AUTOSAR XML (schema 3.1.2)
package /Components/SWC_CoClLASl
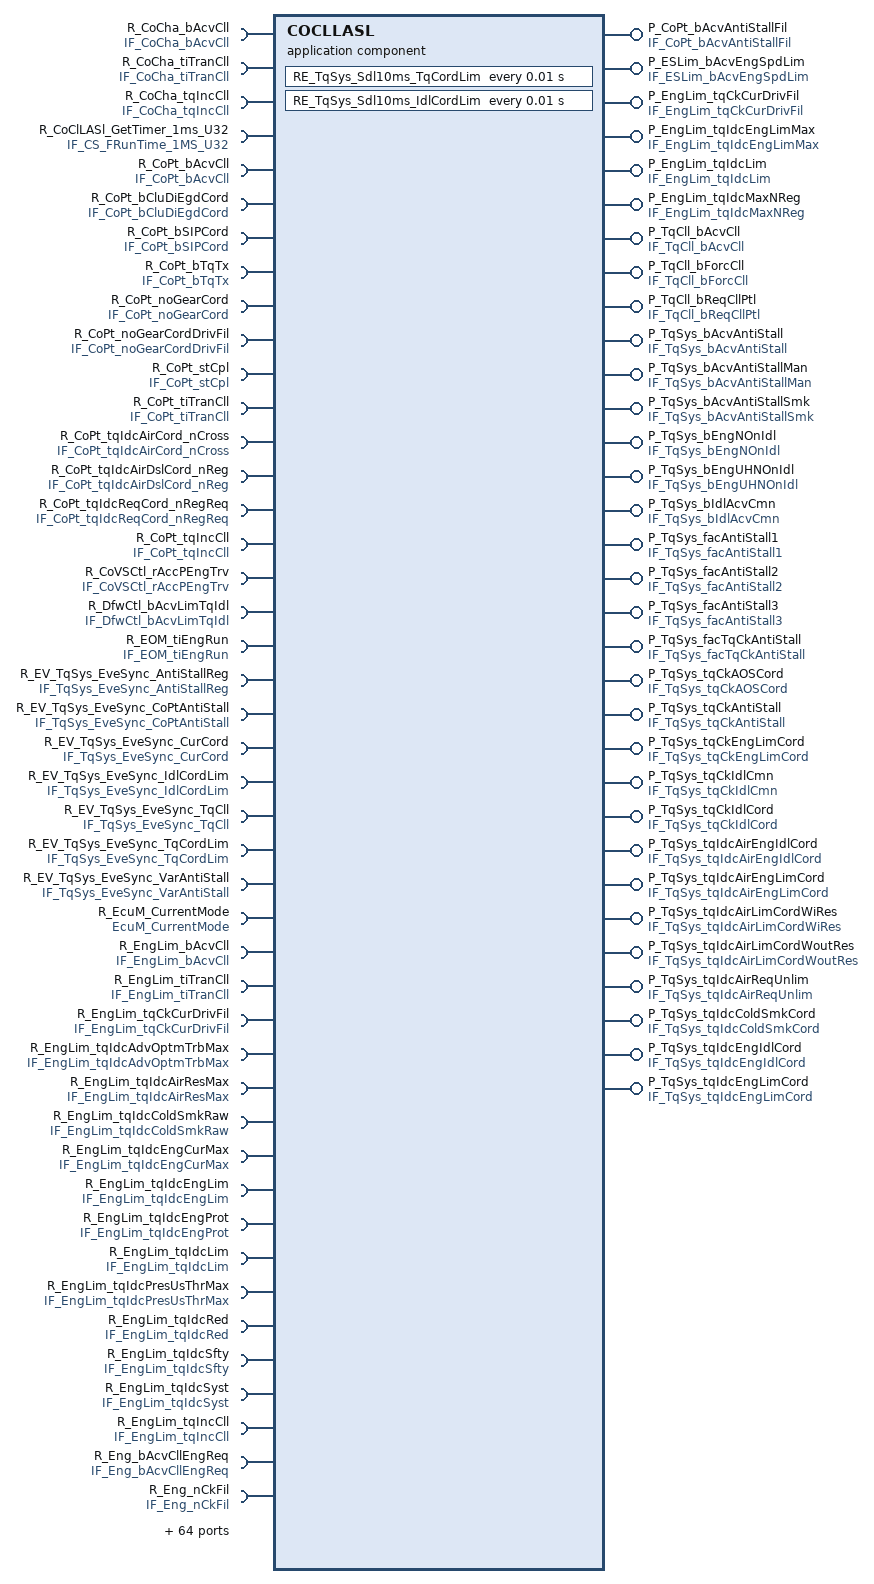
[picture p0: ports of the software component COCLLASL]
  application software component type COCLLASL  # CoClLASl
    32 x provide port:
      P_CoPt_bAcvAntiStallFil: unqueued-sender-com-spec{data-element=CoPt_bAcvAntiStallFil, can-invalidate=false, init-value=ConstantValue}, provided-interface=IF_CoPt_bAcvAntiStallFil  # Requirement: 01552_10_01788-CoClLASl.I103(0)
      P_ESLim_bAcvEngSpdLim: unqueued-sender-com-spec{data-element=ESLim_bAcvEngSpdLim, can-invalidate=false, init-value=ConstantValue1}, provided-interface=IF_ESLim_bAcvEngSpdLim  # Requirement: 01552_10_01788-CoClLASl.I082(0)
      P_EngLim_tqCkCurDrivFil: unqueued-sender-com-spec{data-element=EngLim_tqCkCurDrivFil, can-invalidate=false, init-value=ConstantValue3}, provided-interface=IF_EngLim_tqCkCurDrivFil  # Requirement: 01552_10_01788-CoClLASl.I083(0)
      P_EngLim_tqIdcEngLimMax: unqueued-sender-com-spec{data-element=EngLim_tqIdcEngLimMax, can-invalidate=false, init-value=ConstantValue5}, provided-interface=IF_EngLim_tqIdcEngLimMax  # Requirement: 01552_10_01788-CoClLASl.I086(0)
      P_EngLim_tqIdcLim: unqueued-sender-com-spec{data-element=EngLim_tqIdcLim, can-invalidate=false, init-value=ConstantValue7}, provided-interface=IF_EngLim_tqIdcLim  # Requirement: 01552_10_01788-CoClLASl.I087(0)
      P_EngLim_tqIdcMaxNReg: unqueued-sender-com-spec{data-element=EngLim_tqIdcMaxNReg, can-invalidate=false, init-value=ConstantValue9}, provided-interface=IF_EngLim_tqIdcMaxNReg  # Requirement: 01552_10_01788-CoClLASl.I088(0)
      P_TqCll_bAcvCll: unqueued-sender-com-spec{data-element=TqCll_bAcvCll, can-invalidate=false, init-value=ConstantValue11}, provided-interface=IF_TqCll_bAcvCll  # Requirement: 01552_10_01788-CoClLASl.I048(0)
      P_TqCll_bForcCll: unqueued-sender-com-spec{data-element=TqCll_bForcCll, can-invalidate=false, init-value=ConstantValue13}, provided-interface=IF_TqCll_bForcCll  # Requirement: 01552_10_01788-CoClLASl.I049(0)
      P_TqCll_bReqCllPtl: unqueued-sender-com-spec{data-element=TqCll_bReqCllPtl, can-invalidate=false, init-value=ConstantValue15}, provided-interface=IF_TqCll_bReqCllPtl  # Requirement: 01552_10_01788-CoClLASl.I047(0)
      P_TqSys_bAcvAntiStall: unqueued-sender-com-spec{data-element=TqSys_bAcvAntiStall, can-invalidate=false, init-value=ConstantValue17}, provided-interface=IF_TqSys_bAcvAntiStall  # Requirement: 01552_10_01788-CoClLASl.I003(0)
      P_TqSys_bAcvAntiStallMan: unqueued-sender-com-spec{data-element=TqSys_bAcvAntiStallMan, can-invalidate=false, init-value=ConstantValue19}, provided-interface=IF_TqSys_bAcvAntiStallMan  # Requirement: 01552_10_01788-CoClLASl.I146(0)
      P_TqSys_bAcvAntiStallSmk: unqueued-sender-com-spec{data-element=TqSys_bAcvAntiStallSmk, can-invalidate=false, init-value=ConstantValue21}, provided-interface=IF_TqSys_bAcvAntiStallSmk  # Requirement: 01552_10_01788-CoClLASl.I102(0)
      P_TqSys_bEngNOnIdl: unqueued-sender-com-spec{data-element=TqSys_bEngNOnIdl, can-invalidate=false, init-value=ConstantValue23}, provided-interface=IF_TqSys_bEngNOnIdl  # Requirement: 01552_10_01788-CoClLASl.I004(0)
      P_TqSys_bEngUHNOnIdl: unqueued-sender-com-spec{data-element=TqSys_bEngUHNOnIdl, can-invalidate=false, init-value=ConstantValue25}, provided-interface=IF_TqSys_bEngUHNOnIdl  # Requirement: 01552_10_01788-CoClLASl.I005(0)
      P_TqSys_bIdlAcvCmn: unqueued-sender-com-spec{data-element=TqSys_bIdlAcvCmn, can-invalidate=false, init-value=ConstantValue27}, provided-interface=IF_TqSys_bIdlAcvCmn  # Requirement: 01552_10_01788-CoClLASl.I006(0)
      P_TqSys_facAntiStall1: unqueued-sender-com-spec{data-element=TqSys_facAntiStall1, can-invalidate=false, init-value=ConstantValue29}, provided-interface=IF_TqSys_facAntiStall1  # Requirement: 01552_10_01788-CoClLASl.I112(1)
      P_TqSys_facAntiStall2: unqueued-sender-com-spec{data-element=TqSys_facAntiStall2, can-invalidate=false, init-value=ConstantValue31}, provided-interface=IF_TqSys_facAntiStall2  # Requirement: 01552_10_01788-CoClLASl.I113(1)
      P_TqSys_facAntiStall3: unqueued-sender-com-spec{data-element=TqSys_facAntiStall3, can-invalidate=false, init-value=ConstantValue33}, provided-interface=IF_TqSys_facAntiStall3  # Requirement: 01552_10_01788-CoClLASl.I114(1)
      P_TqSys_facTqCkAntiStall: unqueued-sender-com-spec{data-element=TqSys_facTqCkAntiStall, can-invalidate=false, init-value=ConstantValue35}, provided-interface=IF_TqSys_facTqCkAntiStall  # Requirement: 01552_10_01788-CoClLASl.I115(1)
      P_TqSys_tqCkAOSCord: unqueued-sender-com-spec{data-element=TqSys_tqCkAOSCord, can-invalidate=false, init-value=ConstantValue37}, provided-interface=IF_TqSys_tqCkAOSCord  # Requirement: 01552_10_01788-CoClLASl.I076(0)
      P_TqSys_tqCkAntiStall: unqueued-sender-com-spec{data-element=TqSys_tqCkAntiStall, can-invalidate=false, init-value=ConstantValue39}, provided-interface=IF_TqSys_tqCkAntiStall  # Requirement: 01552_10_01788-CoClLASl.I147(1)
      P_TqSys_tqCkEngLimCord: unqueued-sender-com-spec{data-element=TqSys_tqCkEngLimCord, can-invalidate=false, init-value=ConstantValue41}, provided-interface=IF_TqSys_tqCkEngLimCord  # Requirement: 01552_10_01788-CoClLASl.I050(0)
      P_TqSys_tqCkIdlCmn: unqueued-sender-com-spec{data-element=TqSys_tqCkIdlCmn, can-invalidate=false, init-value=ConstantValue43}, provided-interface=IF_TqSys_tqCkIdlCmn  # Requirement: 01552_10_01788-CoClLASl.I007(0)
      P_TqSys_tqCkIdlCord: unqueued-sender-com-spec{data-element=TqSys_tqCkIdlCord, can-invalidate=false, init-value=ConstantValue45}, provided-interface=IF_TqSys_tqCkIdlCord  # Requirement: 01552_10_01788-CoClLASl.I008(0)
      P_TqSys_tqIdcAirEngIdlCord: unqueued-sender-com-spec{data-element=TqSys_tqIdcAirEngIdlCord, can-invalidate=false, init-value=ConstantValue47}, provided-interface=IF_TqSys_tqIdcAirEngIdlCord  # Requirement: 01552_10_01788-CoClLASl.I001(0)
      P_TqSys_tqIdcAirEngLimCord: unqueued-sender-com-spec{data-element=TqSys_tqIdcAirEngLimCord, can-invalidate=false, init-value=ConstantValue49}, provided-interface=IF_TqSys_tqIdcAirEngLimCord  # Requirement: 01552_10_01788-CoClLASl.I009(0)
      P_TqSys_tqIdcAirLimCordWiRes: unqueued-sender-com-spec{data-element=TqSys_tqIdcAirLimCordWiRes, can-invalidate=false, init-value=ConstantValue51}, provided-interface=IF_TqSys_tqIdcAirLimCordWiRes  # Requirement: 01552_10_01788-CoClLASl.I010(1)
      P_TqSys_tqIdcAirLimCordWoutRes: unqueued-sender-com-spec{data-element=TqSys_tqIdcAirLimCordWoutRes, can-invalidate=false, init-value=ConstantValue53}, provided-interface=IF_TqSys_tqIdcAirLimCordWoutRes  # Requirement: 01552_10_01788-CoClLASl.I011(0)
      P_TqSys_tqIdcAirReqUnlim: unqueued-sender-com-spec{data-element=TqSys_tqIdcAirReqUnlim, can-invalidate=false, init-value=ConstantValue55}, provided-interface=IF_TqSys_tqIdcAirReqUnlim  # Requirement: 01552_10_01788-CoClLASl.I002(0)
      P_TqSys_tqIdcColdSmkCord: unqueued-sender-com-spec{data-element=TqSys_tqIdcColdSmkCord, can-invalidate=false, init-value=ConstantValue57}, provided-interface=IF_TqSys_tqIdcColdSmkCord  # Requirement: 01552_10_01788-CoClLASl.I144(0)
      P_TqSys_tqIdcEngIdlCord: unqueued-sender-com-spec{data-element=TqSys_tqIdcEngIdlCord, can-invalidate=false, init-value=ConstantValue59}, provided-interface=IF_TqSys_tqIdcEngIdlCord  # Requirement: 01552_10_01788-CoClLASl.I012(0)
      P_TqSys_tqIdcEngLimCord: unqueued-sender-com-spec{data-element=TqSys_tqIdcEngLimCord, can-invalidate=false, init-value=ConstantValue61}, provided-interface=IF_TqSys_tqIdcEngLimCord  # Requirement: 01552_10_01788-CoClLASl.I013(0)
    108 x require port:
      R_CoCha_bAcvCll: unqueued-receiver-com-spec{data-element=CoCha_bAcvCll, init-value=ConstantValue63, resync-time=0}, required-interface=IF_CoCha_bAcvCll  # Requirement: 01552_10_01788-CoClLASl.I051(0)
      R_CoCha_tiTranCll: unqueued-receiver-com-spec{data-element=CoCha_tiTranCll, init-value=ConstantValue65, resync-time=0}, required-interface=IF_CoCha_tiTranCll  # Requirement: 01552_10_01788-CoClLASl.I052(0)
      R_CoCha_tqIncCll: unqueued-receiver-com-spec{data-element=CoCha_tqIncCll, init-value=ConstantValue67, resync-time=0}, required-interface=IF_CoCha_tqIncCll  # Requirement: 01552_10_01788-CoClLASl.I053(0)
      R_CoClLASl_GetTimer_1ms_U32: required-interface=IF_CS_FRunTime_1MS_U32
      R_CoPt_bAcvCll: unqueued-receiver-com-spec{data-element=CoPt_bAcvCll, init-value=ConstantValue69, resync-time=0}, required-interface=IF_CoPt_bAcvCll  # Requirement: 01552_10_01788-CoClLASl.I054(0)
      R_CoPt_bCluDiEgdCord: unqueued-receiver-com-spec{data-element=CoPt_bCluDiEgdCord, init-value=ConstantValue71, resync-time=0}, required-interface=IF_CoPt_bCluDiEgdCord  # Requirement: 01552_10_01788-CoClLASl.I116(0)
      R_CoPt_bSIPCord: unqueued-receiver-com-spec{data-element=CoPt_bSIPCord, init-value=ConstantValue73, resync-time=0}, required-interface=IF_CoPt_bSIPCord  # Requirement: 01552_10_01788-CoClLASl.I016(0)
      R_CoPt_bTqTx: unqueued-receiver-com-spec{data-element=CoPt_bTqTx, init-value=ConstantValue75, resync-time=0}, required-interface=IF_CoPt_bTqTx  # Requirement: 01552_10_01788-CoClLASl.I105(0)
      R_CoPt_noGearCord: unqueued-receiver-com-spec{data-element=CoPt_noGearCord, init-value=ConstantValue77, resync-time=0}, required-interface=IF_CoPt_noGearCord  # Requirement: 01552_10_01788-CoClLASl.I089(0)
      R_CoPt_noGearCordDrivFil: unqueued-receiver-com-spec{data-element=CoPt_noGearCordDrivFil, init-value=ConstantValue79, resync-time=0}, required-interface=IF_CoPt_noGearCordDrivFil  # Requirement: 01552_10_01788-CoClLASl.I055(0)
      R_CoPt_stCpl: unqueued-receiver-com-spec{data-element=CoPt_stCpl, init-value=ConstantValue81, resync-time=0}, required-interface=IF_CoPt_stCpl  # Requirement: 01552_10_01788-CoClLASl.I106(0)
      R_CoPt_tiTranCll: unqueued-receiver-com-spec{data-element=CoPt_tiTranCll, init-value=ConstantValue83, resync-time=0}, required-interface=IF_CoPt_tiTranCll  # Requirement: 01552_10_01788-CoClLASl.I056(0)
      R_CoPt_tqIdcAirCord_nCross: unqueued-receiver-com-spec{data-element=CoPt_tqIdcAirCord_nCross, init-value=ConstantValue85, resync-time=0}, required-interface=IF_CoPt_tqIdcAirCord_nCross  # Requirement: 01552_10_01788-CoClLASl.I017(0)
      R_CoPt_tqIdcAirDslCord_nReg: unqueued-receiver-com-spec{data-element=CoPt_tqIdcAirDslCord_nReg, init-value=ConstantValue87, resync-time=0}, required-interface=IF_CoPt_tqIdcAirDslCord_nReg  # Requirement: 01552_10_01788-CoClLASl.I018(0)
      R_CoPt_tqIdcReqCord_nRegReq: unqueued-receiver-com-spec{data-element=CoPt_tqIdcReqCord_nRegReq, init-value=ConstantValue89, resync-time=0}, required-interface=IF_CoPt_tqIdcReqCord_nRegReq  # Requirement: 01552_10_01788-CoClLASl.I019(0)
      R_CoPt_tqIncCll: unqueued-receiver-com-spec{data-element=CoPt_tqIncCll, init-value=ConstantValue91, resync-time=0}, required-interface=IF_CoPt_tqIncCll  # Requirement: 01552_10_01788-CoClLASl.I057(0)
      R_CoVSCtl_rAccPEngTrv: unqueued-receiver-com-spec{data-element=CoVSCtl_rAccPEngTrv, init-value=ConstantValue93, resync-time=0}, required-interface=IF_CoVSCtl_rAccPEngTrv  # Requirement: 01552_10_01788-CoClLASl.I020(0)
      R_DfwCtl_bAcvLimTqIdl: unqueued-receiver-com-spec{data-element=DfwCtl_bAcvLimTqIdl, init-value=ConstantValue95, resync-time=0}, required-interface=IF_DfwCtl_bAcvLimTqIdl  # Requirement: 01552_10_01788-CoClLASl.I021(2)
      R_EOM_tiEngRun: unqueued-receiver-com-spec{data-element=EOM_tiEngRun, init-value=ConstantValue97, resync-time=0}, required-interface=IF_EOM_tiEngRun  # Requirement: 01552_10_01788-CoClLASl.I117(0)
      R_EV_TqSys_EveSync_AntiStallReg: unqueued-receiver-com-spec{data-element=EV_TqSys_EveSync_AntiStallReg, init-value=ConstantValue99, resync-time=0}, required-interface=IF_TqSys_EveSync_AntiStallReg
      R_EV_TqSys_EveSync_CoPtAntiStall: unqueued-receiver-com-spec{data-element=EV_TqSys_EveSync_CoPtAntiStall, init-value=ConstantValue101, resync-time=0}, required-interface=IF_TqSys_EveSync_CoPtAntiStall
      R_EV_TqSys_EveSync_CurCord: unqueued-receiver-com-spec{data-element=EV_TqSys_EveSync_CurCord, init-value=ConstantValue103, resync-time=0}, required-interface=IF_TqSys_EveSync_CurCord
      R_EV_TqSys_EveSync_IdlCordLim: unqueued-receiver-com-spec{data-element=EV_TqSys_EveSync_IdlCordLim, init-value=ConstantValue105, resync-time=0}, required-interface=IF_TqSys_EveSync_IdlCordLim
      R_EV_TqSys_EveSync_TqCll: unqueued-receiver-com-spec{data-element=EV_TqSys_EveSync_TqCll, init-value=ConstantValue107, resync-time=0}, required-interface=IF_TqSys_EveSync_TqCll
      R_EV_TqSys_EveSync_TqCordLim: unqueued-receiver-com-spec{data-element=EV_TqSys_EveSync_TqCordLim, init-value=ConstantValue109, resync-time=0}, required-interface=IF_TqSys_EveSync_TqCordLim
      R_EV_TqSys_EveSync_VarAntiStall: unqueued-receiver-com-spec{data-element=EV_TqSys_EveSync_VarAntiStall, init-value=ConstantValue111, resync-time=0}, required-interface=IF_TqSys_EveSync_VarAntiStall
      R_EcuM_CurrentMode: required-interface=EcuM_CurrentMode  # Requirement: 01552_09_00532-SSTG-C007(0)
      R_EngLim_bAcvCll: unqueued-receiver-com-spec{data-element=EngLim_bAcvCll, init-value=ConstantValue113, resync-time=0}, required-interface=IF_EngLim_bAcvCll  # Requirement: 01552_10_01788-CoClLASl.I059(0)
      R_EngLim_tiTranCll: unqueued-receiver-com-spec{data-element=EngLim_tiTranCll, init-value=ConstantValue115, resync-time=0}, required-interface=IF_EngLim_tiTranCll  # Requirement: 01552_10_01788-CoClLASl.I060(0)
      R_EngLim_tqCkCurDrivFil: unqueued-receiver-com-spec{data-element=EngLim_tqCkCurDrivFil, init-value=ConstantValue117, resync-time=0}, required-interface=IF_EngLim_tqCkCurDrivFil  # Requirement: 01552_10_01788-CoClLASl.I077(0)
      R_EngLim_tqIdcAdvOptmTrbMax: unqueued-receiver-com-spec{data-element=EngLim_tqIdcAdvOptmTrbMax, init-value=ConstantValue119, resync-time=0}, required-interface=IF_EngLim_tqIdcAdvOptmTrbMax  # Requirement: 01552_10_01788-CoClLASl.I090(0)
      R_EngLim_tqIdcAirResMax: unqueued-receiver-com-spec{data-element=EngLim_tqIdcAirResMax, init-value=ConstantValue121, resync-time=0}, required-interface=IF_EngLim_tqIdcAirResMax  # Requirement: 01552_10_01788-CoClLASl.I091(0)
      R_EngLim_tqIdcColdSmkRaw: unqueued-receiver-com-spec{data-element=EngLim_tqIdcColdSmkRaw, init-value=ConstantValue123, resync-time=0}, required-interface=IF_EngLim_tqIdcColdSmkRaw  # Requirement: 01552_10_01788-CoClLASl.I024(0)
      R_EngLim_tqIdcEngCurMax: unqueued-receiver-com-spec{data-element=EngLim_tqIdcEngCurMax, init-value=ConstantValue125, resync-time=0}, required-interface=IF_EngLim_tqIdcEngCurMax  # Requirement: 01552_10_01788-CoClLASl.I061(0)
      R_EngLim_tqIdcEngLim: unqueued-receiver-com-spec{data-element=EngLim_tqIdcEngLim, init-value=ConstantValue127, resync-time=0}, required-interface=IF_EngLim_tqIdcEngLim  # Requirement: 01552_10_01788-CoClLASl.I092(0)
      R_EngLim_tqIdcEngProt: unqueued-receiver-com-spec{data-element=EngLim_tqIdcEngProt, init-value=ConstantValue129, resync-time=0}, required-interface=IF_EngLim_tqIdcEngProt  # Requirement: 01552_10_01788-CoClLASl.I093(0)
      R_EngLim_tqIdcLim: unqueued-receiver-com-spec{data-element=EngLim_tqIdcLim, init-value=ConstantValue131, resync-time=0}, required-interface=IF_EngLim_tqIdcLim  # Requirement: 01552_10_01788-CoClLASl.I025(0)
      R_EngLim_tqIdcPresUsThrMax: unqueued-receiver-com-spec{data-element=EngLim_tqIdcPresUsThrMax, init-value=ConstantValue133, resync-time=0}, required-interface=IF_EngLim_tqIdcPresUsThrMax  # Requirement: 01552_10_01788-CoClLASl.I094(0)
      R_EngLim_tqIdcRed: unqueued-receiver-com-spec{data-element=EngLim_tqIdcRed, init-value=ConstantValue135, resync-time=0}, required-interface=IF_EngLim_tqIdcRed  # Requirement: 01552_10_01788-CoClLASl.I026(0)
      R_EngLim_tqIdcSfty: unqueued-receiver-com-spec{data-element=EngLim_tqIdcSfty, init-value=ConstantValue137, resync-time=0}, required-interface=IF_EngLim_tqIdcSfty  # Requirement: 01552_10_01788-CoClLASl.I095(0)
      R_EngLim_tqIdcSyst: unqueued-receiver-com-spec{data-element=EngLim_tqIdcSyst, init-value=ConstantValue139, resync-time=0}, required-interface=IF_EngLim_tqIdcSyst  # Requirement: 01552_10_01788-CoClLASl.I096(0)
      R_EngLim_tqIncCll: unqueued-receiver-com-spec{data-element=EngLim_tqIncCll, init-value=ConstantValue141, resync-time=0}, required-interface=IF_EngLim_tqIncCll  # Requirement: 01552_10_01788-CoClLASl.I062(0)
      R_Eng_bAcvCllEngReq: unqueued-receiver-com-spec{data-element=Eng_bAcvCllEngReq, init-value=ConstantValue143, resync-time=0}, required-interface=IF_Eng_bAcvCllEngReq  # Requirement: 01552_10_01788-CoClLASl.I143(0)
      R_Eng_nCkFil: unqueued-receiver-com-spec{data-element=Eng_nCkFil, init-value=ConstantValue145, resync-time=0}, required-interface=IF_Eng_nCkFil  # Requirement: 01552_10_01788-CoClLASl.I058(0)
      R_CoBrk_bAcvBrk: unqueued-receiver-com-spec{data-element=CoBrk_bAcvBrk, init-value=ConstantValue2, resync-time=0}, required-interface=IF_CoBrk_bAcvBrk  # R_Ext_bSecBrkPedPrssMes | Requirement: 01552_10_01788-CoClLASl.I152(0)
      R_Ext_nEng: unqueued-receiver-com-spec{data-element=Ext_nEng, init-value=ConstantValue149, resync-time=0}, required-interface=IF_Ext_nEng  # Requirement: 01552_10_01788-CoClLASl.I027(0)
      R_Ext_nEng1: unqueued-receiver-com-spec{data-element=Ext_nEng1, init-value=ConstantValue151, resync-time=0}, required-interface=IF_Ext_nEng1  # Requirement: 01552_10_01788-CoClLASl.I123(1)
      R_Ext_nEng2: unqueued-receiver-com-spec{data-element=Ext_nEng2, init-value=ConstantValue153, resync-time=0}, required-interface=IF_Ext_nEng2  # Requirement: 01552_10_01788-CoClLASl.I126(1)
      R_Ext_stGBxCf: unqueued-receiver-com-spec{data-element=Ext_stGBxCf, init-value=ConstantValue155, resync-time=0}, required-interface=IF_Ext_stGBxCf  # Requirement: 01552_10_01788-CoClLASl.I028(0)
      R_Ext_tCoMes: unqueued-receiver-com-spec{data-element=Ext_tCoMes, init-value=ConstantValue157, resync-time=0}, required-interface=IF_Ext_tCoMes  # Requirement: 01552_10_01788-CoClLASl.I108(0)
      R_Ext_tiTDC: unqueued-receiver-com-spec{data-element=Ext_tiTDC, init-value=ConstantValue159, resync-time=0}, required-interface=IF_Ext_tiTDC  # Requirement: 01552_10_01788-CoClLASl.I029(0)
      R_FRM_bInhCoPtBrk: required-interface=FunctionInhibition  # Requirement: 01552_10_01788-CoClLASl.I205(0)
      R_FRM_bInhCoPtSpdVeh: required-interface=FunctionInhibition  # Requirement: 01552_10_01788-CoClLASl.I206(0)
      R_FRM_bInhCoPtStPt: required-interface=FunctionInhibition  # Requirement: 01552_10_01788-CoClLASl.I207(0)
      R_FRM_bInhCoPtTCo: required-interface=FunctionInhibition  # Requirement: 01552_10_01788-CoClLASl.I201(0)
      R_FRM_bInhTqCll: required-interface=FunctionInhibition  # Requirement: 01552_10_01788-CoClLASl.I204(0)
      R_IdlSys_bAcvAntiStall: unqueued-receiver-com-spec{data-element=IdlSys_bAcvAntiStall, init-value=ConstantValue161, resync-time=0}, required-interface=IF_IdlSys_bAcvAntiStall  # Requirement: 01552_10_01788-CoClLASl.I030(0)
      R_IdlSys_bAcvCll: unqueued-receiver-com-spec{data-element=IdlSys_bAcvCll, init-value=ConstantValue163, resync-time=0}, required-interface=IF_IdlSys_bAcvCll  # Requirement: 01552_10_01788-CoClLASl.I148(0)
      R_IdlSys_bAcvIdlCtl: unqueued-receiver-com-spec{data-element=IdlSys_bAcvIdlCtl, init-value=ConstantValue165, resync-time=0}, required-interface=IF_IdlSys_bAcvIdlCtl  # Requirement: 01552_10_01788-CoClLASl.I031(0)
      R_IdlSys_tiTranCll: unqueued-receiver-com-spec{data-element=IdlSys_tiTranCll, init-value=ConstantValue167, resync-time=0}, required-interface=IF_IdlSys_tiTranCll  # Requirement: 01552_10_01788-CoClLASl.I063(0)
      R_IdlSys_tqIdcAirIdl: unqueued-receiver-com-spec{data-element=IdlSys_tqIdcAirIdl, init-value=ConstantValue169, resync-time=0}, required-interface=IF_IdlSys_tqIdcAirIdl  # Requirement: 01552_10_01788-CoClLASl.I032(0)
      R_IdlSys_tqIdcIdl: unqueued-receiver-com-spec{data-element=IdlSys_tqIdcIdl, init-value=ConstantValue171, resync-time=0}, required-interface=IF_IdlSys_tqIdcIdl  # Requirement: 01552_10_01788-CoClLASl.I033(0)
      R_IdlSys_tqIncCll: unqueued-receiver-com-spec{data-element=IdlSys_tqIncCll, init-value=ConstantValue173, resync-time=0}, required-interface=IF_IdlSys_tqIncCll  # Requirement: 01552_10_01788-CoClLASl.I064(0)
      R_ThMgt_tqIdcLimReq: unqueued-receiver-com-spec{data-element=ThMgt_tqIdcLimReq, init-value=ConstantValue175, resync-time=0}, required-interface=IF_ThMgt_tqIdcLimReq  # Requirement: 01552_10_01788-CoClLASl.I097(0)
      R_TqAdvMin_bAcvCll: unqueued-receiver-com-spec{data-element=TqAdvMin_bAcvCll, init-value=ConstantValue177, resync-time=0}, required-interface=IF_TqAdvMin_bAcvCll  # Requirement: 01552_10_01788-CoClLASl.I149(0)
      R_TqAdvMin_tiTranCll: unqueued-receiver-com-spec{data-element=TqAdvMin_tiTranCll, init-value=ConstantValue179, resync-time=0}, required-interface=IF_TqAdvMin_tiTranCll  # Requirement: 01552_10_01788-CoClLASl.I150(0)
      R_TqAdvMin_tqIncCll: unqueued-receiver-com-spec{data-element=TqAdvMin_tqIncCll, init-value=ConstantValue181, resync-time=0}, required-interface=IF_TqAdvMin_tqIncCll  # Requirement: 01552_10_01788-CoClLASl.I151(0)
      R_TqCmp_tqSumLossCmp: unqueued-receiver-com-spec{data-element=TqCmp_tqSumLossCmp, init-value=ConstantValue183, resync-time=0}, required-interface=IF_TqCmp_tqSumLossCmp  # Requirement: 01552_10_01788-CoClLASl.I034(0)
      R_TqDem_tqIdcLimNReg: unqueued-receiver-com-spec{data-element=TqDem_tqIdcLimNReg, init-value=ConstantValue185, resync-time=0}, required-interface=IF_TqDem_tqIdcLimNReg  # Requirement: 01552_10_01788-CoClLASl.I098(0)
      R_TqRes_bAcvCll: unqueued-receiver-com-spec{data-element=TqRes_bAcvCll, init-value=ConstantValue187, resync-time=0}, required-interface=IF_TqRes_bAcvCll  # Requirement: 01552_10_01788-CoClLASl.I065(0)
      R_TqRes_tiTranCll: unqueued-receiver-com-spec{data-element=TqRes_tiTranCll, init-value=ConstantValue189, resync-time=0}, required-interface=IF_TqRes_tiTranCll  # Requirement: 01552_10_01788-CoClLASl.I066(0)
      R_TqRes_tqIncCll: unqueued-receiver-com-spec{data-element=TqRes_tqIncCll, init-value=ConstantValue191, resync-time=0}, required-interface=IF_TqRes_tqIncCll  # Requirement: 01552_10_01788-CoClLASl.I067(1)
      R_TqRes_tqMaxRes: unqueued-receiver-com-spec{data-element=TqRes_tqMaxRes, init-value=ConstantValue193, resync-time=0}, required-interface=IF_TqRes_tqMaxRes  # Requirement: 01552_10_01788-CoClLASl.I035(0)
      R_TqSys_bAOSAcv: unqueued-receiver-com-spec{data-element=TqSys_bAOSAcv, init-value=ConstantValue195, resync-time=0}, required-interface=IF_TqSys_bAOSAcv  # Requirement: 01552_10_01788-CoClLASl.I069(0)
      R_TqSys_bAcvAntiStallMan: unqueued-receiver-com-spec{data-element=TqSys_bAcvAntiStallMan, init-value=ConstantValue197, resync-time=0}, required-interface=IF_TqSys_bAcvAntiStallMan  # Requirement: 01552_10_01788-CoClLASl.I037(0)
      R_TqSys_bAcvCll: unqueued-receiver-com-spec{data-element=TqSys_bAcvCll, init-value=ConstantValue199, resync-time=0}, required-interface=IF_TqSys_bAcvCll  # Requirement: 01552_10_01788-CoClLASl.I068(0)
      R_TqSys_bEngNOnIdl: unqueued-receiver-com-spec{data-element=TqSys_bEngNOnIdl, init-value=ConstantValue201, resync-time=0}, required-interface=IF_TqSys_bEngNOnIdl  # Requirement: 01552_10_01788-CoClLASl.I070(0)
      R_TqSys_bIdlAcv: unqueued-receiver-com-spec{data-element=TqSys_bIdlAcv, init-value=ConstantValue203, resync-time=0}, required-interface=IF_TqSys_bIdlAcv  # Requirement: 01552_10_01788-CoClLASl.I014(0)
      R_TqSys_bIdlAcvCmn: unqueued-receiver-com-spec{data-element=TqSys_bIdlAcvCmn, init-value=ConstantValue205, resync-time=0}, required-interface=IF_TqSys_bIdlAcvCmn  # Requirement: 01552_10_01788-CoClLASl.I118(0)
      R_TqSys_bTypFu: unqueued-receiver-com-spec{data-element=TqSys_bTypFu, init-value=ConstantValue207, resync-time=0}, required-interface=IF_TqSys_bTypFu  # Requirement: 01552_10_01788-CoClLASl.I038(0)
      R_TqSys_facAntiStall1: unqueued-receiver-com-spec{data-element=TqSys_facAntiStall1, init-value=ConstantValue209, resync-time=0}, required-interface=IF_TqSys_facAntiStall1  # Requirement: 01552_10_01788-CoClLASl.I124(0)
      R_TqSys_facAntiStall2: unqueued-receiver-com-spec{data-element=TqSys_facAntiStall2, init-value=ConstantValue211, resync-time=0}, required-interface=IF_TqSys_facAntiStall2  # Requirement: 01552_10_01788-CoClLASl.I125(0)
      R_TqSys_facAntiStall3: unqueued-receiver-com-spec{data-element=TqSys_facAntiStall3, init-value=ConstantValue213, resync-time=0}, required-interface=IF_TqSys_facAntiStall3  # Requirement: 01552_10_01788-CoClLASl.I127(1)
      R_TqSys_facReqExhTempProt: unqueued-receiver-com-spec{data-element=TqSys_facReqExhTempProt, init-value=ConstantValue215, resync-time=0}, required-interface=IF_TqSys_facReqExhTempProt  # Requirement: 01552_10_01788-CoClLASl.I040(0)
      R_TqSys_facReqFuelRunDry: unqueued-receiver-com-spec{data-element=TqSys_facReqFuelRunDry, init-value=ConstantValue217, resync-time=0}, required-interface=IF_TqSys_facReqFuelRunDry  # Requirement: 01552_10_01788-CoClLASl.I041(0)
      R_TqSys_facTqCkAntiStall: unqueued-receiver-com-spec{data-element=TqSys_facTqCkAntiStall, init-value=ConstantValue219, resync-time=0}, required-interface=IF_TqSys_facTqCkAntiStall  # Requirement: 01552_10_01788-CoClLASl.I128(1)
      R_TqSys_nTarDynIdl: unqueued-receiver-com-spec{data-element=TqSys_nTarDynIdl, init-value=ConstantValue221, resync-time=0}, required-interface=IF_TqSys_nTarDynIdl  # Requirement: 01552_10_01788-CoClLASl.I120(0)
      R_TqSys_nTarIdl: unqueued-receiver-com-spec{data-element=TqSys_nTarIdl, init-value=ConstantValue223, resync-time=0}, required-interface=IF_TqSys_nTarIdl  # Requirement: 01552_10_01788-CoClLASl.I042(0)
      R_TqSys_tiTranCll: unqueued-receiver-com-spec{data-element=TqSys_tiTranCll, init-value=ConstantValue225, resync-time=0}, required-interface=IF_TqSys_tiTranCll  # Requirement: 01552_10_01788-CoClLASl.I072(0)
      R_TqSys_tqAOSCVC: unqueued-receiver-com-spec{data-element=TqSys_tqAOSCVC, init-value=ConstantValue227, resync-time=0}, required-interface=IF_TqSys_tqAOSCVC  # Requirement: 01552_10_01788-CoClLASl.I079(0)
      R_TqSys_tqCkAOSCor: unqueued-receiver-com-spec{data-element=TqSys_tqCkAOSCor, init-value=ConstantValue229, resync-time=0}, required-interface=IF_TqSys_tqCkAOSCor  # Requirement: 01552_10_01788-CoClLASl.I080(0)
      R_TqSys_tqCkAntiStall: unqueued-receiver-com-spec{data-element=TqSys_tqCkAntiStall, init-value=ConstantValue231, resync-time=0}, required-interface=IF_TqSys_tqCkAntiStall  # Requirement: 01552_10_01788-CoClLASl.I044(0)
      R_TqSys_tqCkEngLimCord: unqueued-receiver-com-spec{data-element=TqSys_tqCkEngLimCord, init-value=ConstantValue233, resync-time=0}, required-interface=IF_TqSys_tqCkEngLimCord  # Requirement: 01552_10_01788-CoClLASl.I081(0)
      R_TqSys_tqCkIdl: unqueued-receiver-com-spec{data-element=TqSys_tqCkIdl, init-value=ConstantValue235, resync-time=0}, required-interface=IF_TqSys_tqCkIdl  # Requirement: 01552_10_01788-CoClLASl.I129(1)
      R_TqSys_tqCkIdlCord: unqueued-receiver-com-spec{data-element=TqSys_tqCkIdlCord, init-value=ConstantValue237, resync-time=0}, required-interface=IF_TqSys_tqCkIdlCord  # Requirement: 01552_10_01788-CoClLASl.I145(0)
      R_TqSys_tqCkIdlMax: unqueued-receiver-com-spec{data-element=TqSys_tqCkIdlMax, init-value=ConstantValue239, resync-time=0}, required-interface=IF_TqSys_tqCkIdlMax  # Requirement: 01552_10_01788-CoClLASl.I131(1)
      R_TqSys_tqCkIdlMin: unqueued-receiver-com-spec{data-element=TqSys_tqCkIdlMin, init-value=ConstantValue241, resync-time=0}, required-interface=IF_TqSys_tqCkIdlMin  # Requirement: 01552_10_01788-CoClLASl.I130(1)
      R_TqSys_tqIdcAirLimCordWiRes: unqueued-receiver-com-spec{data-element=TqSys_tqIdcAirLimCordWiRes, init-value=ConstantValue243, resync-time=0}, required-interface=IF_TqSys_tqIdcAirLimCordWiRes  # Requirement: 01552_10_01788-CoClLASl.I101(0)
      R_TqSys_tqIdcAirReqGen: unqueued-receiver-com-spec{data-element=TqSys_tqIdcAirReqGen, init-value=ConstantValue245, resync-time=0}, required-interface=IF_TqSys_tqIdcAirReqGen  # Requirement: 01552_10_01788-CoClLASl.I073(2)
      R_TqSys_tqIdcEngLimCord: unqueued-receiver-com-spec{data-element=TqSys_tqIdcEngLimCord, init-value=ConstantValue247, resync-time=0}, required-interface=IF_TqSys_tqIdcEngLimCord  # Requirement: 01552_10_01788-CoClLASl.I074(0)
      R_TqSys_tqIdcLvlSBPA: unqueued-receiver-com-spec{data-element=TqSys_tqIdcLvlSBPA, init-value=ConstantValue249, resync-time=0}, required-interface=IF_TqSys_tqIdcLvlSBPA  # Requirement: 01552_10_01788-CoClLASl.I045(0)
      R_TqSys_tqIdcReq: unqueued-receiver-com-spec{data-element=TqSys_tqIdcReq, init-value=ConstantValue251, resync-time=0}, required-interface=IF_TqSys_tqIdcReq  # Requirement: 01552_10_01788-CoClLASl.I121(0)
      R_TqSys_tqIdcSBPA: unqueued-receiver-com-spec{data-element=TqSys_tqIdcSBPA, init-value=ConstantValue253, resync-time=0}, required-interface=IF_TqSys_tqIdcSBPA  # Requirement: 01552_10_01788-CoClLASl.I046(0)
      R_TqSys_tqIncCll: unqueued-receiver-com-spec{data-element=TqSys_tqIncCll, init-value=ConstantValue255, resync-time=0}, required-interface=IF_TqSys_tqIncCll  # Requirement: 01552_10_01788-CoClLASl.I075(0)
      R_TreatTDC_nCkGrd: unqueued-receiver-com-spec{data-element=TreatTDC_nCkGrd, init-value=ConstantValue257, resync-time=0}, required-interface=IF_TreatTDC_nCkGrd  # Requirement: 01552_10_01788-CoClLASl.I110(0)
      R_TreatTDC_nCkTDCDelta: unqueued-receiver-com-spec{data-element=TreatTDC_nCkTDCDelta, init-value=ConstantValue259, resync-time=0}, required-interface=IF_TreatTDC_nCkTDCDelta  # Requirement: 01552_10_01788-CoClLASl.I122(0)
      R_UCE_stSt: required-interface=IF_UCE_stSt  # Requirement: 01552_09_00532-SSTG-C011(0)
      R_Veh_spdVeh: unqueued-receiver-com-spec{data-element=Veh_spdVeh, init-value=ConstantValue261, resync-time=0}, required-interface=IF_Veh_spdVeh  # Requirement: 01552_10_01788-CoClLASl.I111(0)
  136 x constant specification:
    C_Boolean_False
      value:
        boolean literal C_Boolean_False: type=DT_TqSys_bAcvAntiStallAut_irv, value=false
    C_SInt16_32000
      value:
        integer literal C_SInt16_32000: type=DT_EngLim_tqIdcAirLimAfterRes_irv, value=32000
    C_SInt16_32000263
      value:
        integer literal C_SInt16_32000263: type=DT_EngLim_tqIdcAirLim_irv, value=32000
    C_SInt16_32000265
      value:
        integer literal C_SInt16_32000265: type=DT_IdlSys_tqIdcIdlAirSBPA_irv, value=32000
    ConstantValue
      value:
        boolean literal ConstantValue: type=DT_CoPt_bAcvAntiStallFil, value=false
    ConstantValue1
      value:
        boolean literal ConstantValue1: type=DT_ESLim_bAcvEngSpdLim, value=false
    ConstantValue101
      value:
        integer literal ConstantValue101: type=UInt8, value=0
    ConstantValue103
      value:
        integer literal ConstantValue103: type=UInt8, value=0
    ConstantValue105
      value:
        integer literal ConstantValue105: type=UInt8, value=0
    ConstantValue107
      value:
        integer literal ConstantValue107: type=UInt8, value=0
    ConstantValue109
      value:
        integer literal ConstantValue109: type=UInt8, value=0
    ConstantValue11
      value:
        boolean literal ConstantValue11: type=DT_TqCll_bAcvCll, value=false
    ConstantValue111
      value:
        integer literal ConstantValue111: type=UInt8, value=0
    ConstantValue113
      value:
        boolean literal ConstantValue113: type=DT_EngLim_bAcvCll, value=false
    ConstantValue115
      value:
        integer literal ConstantValue115: type=DT_EngLim_tiTranCll, value=0
    ConstantValue117
      value:
        integer literal ConstantValue117: type=DT_EngLim_tqCkCurDrivFil, value=32000
    ConstantValue119
      value:
        integer literal ConstantValue119: type=DT_EngLim_tqIdcAdvOptmTrbMax, value=0
    ConstantValue121
      value:
        integer literal ConstantValue121: type=DT_EngLim_tqIdcAirResMax, value=0
    ConstantValue123
      value:
        integer literal ConstantValue123: type=DT_EngLim_tqIdcColdSmkRaw, value=0
    ConstantValue125
      value:
        integer literal ConstantValue125: type=DT_EngLim_tqIdcEngCurMax, value=32000
    ConstantValue127
      value:
        integer literal ConstantValue127: type=DT_EngLim_tqIdcEngLim, value=32000
    ConstantValue129
      value:
        integer literal ConstantValue129: type=DT_EngLim_tqIdcEngProt, value=32000
    ConstantValue13
      value:
        boolean literal ConstantValue13: type=DT_TqCll_bForcCll, value=false
    ConstantValue131
      value:
        integer literal ConstantValue131: type=DT_EngLim_tqIdcLim, value=32000
    ConstantValue133
      value:
        integer literal ConstantValue133: type=DT_EngLim_tqIdcPresUsThrMax, value=32000
    ConstantValue135
      value:
        integer literal ConstantValue135: type=DT_EngLim_tqIdcRed, value=0
    ConstantValue137
      value:
        integer literal ConstantValue137: type=DT_EngLim_tqIdcSfty, value=32000
    ConstantValue139
      value:
        integer literal ConstantValue139: type=DT_EngLim_tqIdcSyst, value=0
    ConstantValue141
      value:
        integer literal ConstantValue141: type=DT_EngLim_tqIncCll, value=0
    ConstantValue143
      value:
        boolean literal ConstantValue143: type=DT_Eng_bAcvCllEngReq, value=false
    ConstantValue145
      value:
        integer literal ConstantValue145: type=DT_Eng_nCkFil, value=0
    ConstantValue149
      value:
        integer literal ConstantValue149: type=DT_Ext_nEng, value=0
    ConstantValue15
      value:
        boolean literal ConstantValue15: type=DT_TqCll_bReqCllPtl, value=false
    ConstantValue151
      value:
        integer literal ConstantValue151: type=DT_Ext_nEng1, value=0
    ConstantValue153
      value:
        integer literal ConstantValue153: type=DT_Ext_nEng2, value=0
    ConstantValue155
      value:
        integer literal ConstantValue155: type=DT_Ext_stGBxCf, value=0
    ConstantValue157
      value:
        integer literal ConstantValue157: type=DT_Ext_tCoMes, value=20
    ConstantValue159
      value:
        integer literal ConstantValue159: type=DT_Ext_tiTDC, value=100
    ConstantValue161
      value:
        boolean literal ConstantValue161: type=DT_IdlSys_bAcvAntiStall, value=false
    ConstantValue163
      value:
        boolean literal ConstantValue163: type=DT_IdlSys_bAcvCll, value=false
    ConstantValue165
      value:
        boolean literal ConstantValue165: type=DT_IdlSys_bAcvIdlCtl, value=false
    ConstantValue167
      value:
        integer literal ConstantValue167: type=DT_IdlSys_tiTranCll, value=0
    ConstantValue169
      value:
        integer literal ConstantValue169: type=DT_IdlSys_tqIdcAirIdl, value=0
    ConstantValue17
      value:
        boolean literal ConstantValue17: type=DT_TqSys_bAcvAntiStall, value=true
    ConstantValue171
      value:
        integer literal ConstantValue171: type=DT_IdlSys_tqIdcIdl, value=0
    ConstantValue173
      value:
        integer literal ConstantValue173: type=DT_IdlSys_tqIncCll, value=0
    ConstantValue175
      value:
        integer literal ConstantValue175: type=DT_ThMgt_tqIdcLimReq, value=0
    ConstantValue177
      value:
        boolean literal ConstantValue177: type=DT_TqAdvMin_bAcvCll, value=false
    ConstantValue179
      value:
        integer literal ConstantValue179: type=DT_TqAdvMin_tiTranCll, value=0
    ConstantValue181
      value:
        integer literal ConstantValue181: type=DT_TqAdvMin_tqIncCll, value=0
    ConstantValue183
      value:
        integer literal ConstantValue183: type=DT_TqCmp_tqSumLossCmp, value=0
    ConstantValue185
      value:
        integer literal ConstantValue185: type=DT_TqDem_tqIdcLimNReg, value=0
    ConstantValue187
      value:
        boolean literal ConstantValue187: type=DT_TqRes_bAcvCll, value=false
    ConstantValue189
      value:
        integer literal ConstantValue189: type=DT_TqRes_tiTranCll, value=0
    ConstantValue19
      value:
        boolean literal ConstantValue19: type=DT_TqSys_bAcvAntiStallMan, value=false
    ConstantValue191
      value:
        integer literal ConstantValue191: type=DT_TqRes_tqIncCll, value=0
    ConstantValue193
      value:
        integer literal ConstantValue193: type=DT_TqRes_tqMaxRes, value=0
    ConstantValue195
      value:
        boolean literal ConstantValue195: type=DT_TqSys_bAOSAcv, value=false
    ConstantValue197
      value:
        boolean literal ConstantValue197: type=DT_TqSys_bAcvAntiStallMan, value=false
    ConstantValue199
      value:
        boolean literal ConstantValue199: type=DT_TqSys_bAcvCll, value=false
    ConstantValue2
      value:
        boolean literal ConstantValue2: type=DT_CoBrk_bAcvBrk, value=false
    ConstantValue201
      value:
        boolean literal ConstantValue201: type=DT_TqSys_bEngNOnIdl, value=true
    ConstantValue203
      value:
        boolean literal ConstantValue203: type=DT_TqSys_bIdlAcv, value=false
    ConstantValue205
      value:
        boolean literal ConstantValue205: type=DT_TqSys_bIdlAcvCmn, value=true
    ConstantValue207
      value:
        boolean literal ConstantValue207: type=DT_TqSys_bTypFu, value=false
    ConstantValue209
      value:
        integer literal ConstantValue209: type=DT_TqSys_facAntiStall1, value=0
    ConstantValue21
      value:
        boolean literal ConstantValue21: type=DT_TqSys_bAcvAntiStallSmk, value=false
    ConstantValue211
      value:
        integer literal ConstantValue211: type=DT_TqSys_facAntiStall2, value=0
    ConstantValue213
      value:
        integer literal ConstantValue213: type=DT_TqSys_facAntiStall3, value=0
    ConstantValue215
      value:
        integer literal ConstantValue215: type=DT_TqSys_facReqExhTempProt, value=128
    ConstantValue217
      value:
        integer literal ConstantValue217: type=DT_TqSys_facReqFuelRunDry, value=128
    ConstantValue219
      value:
        integer literal ConstantValue219: type=DT_TqSys_facTqCkAntiStall, value=0
    ConstantValue221
      value:
        integer literal ConstantValue221: type=DT_TqSys_nTarDynIdl, value=0
    ConstantValue223
      value:
        integer literal ConstantValue223: type=DT_TqSys_nTarIdl, value=0
    ConstantValue225
      value:
        integer literal ConstantValue225: type=DT_TqSys_tiTranCll, value=0
    ConstantValue227
      value:
        integer literal ConstantValue227: type=DT_TqSys_tqAOSCVC, value=0
    ConstantValue229
      value:
        integer literal ConstantValue229: type=DT_TqSys_tqCkAOSCor, value=0
    ConstantValue23
      value:
        boolean literal ConstantValue23: type=DT_TqSys_bEngNOnIdl, value=true
    ConstantValue231
      value:
        integer literal ConstantValue231: type=DT_TqSys_tqCkAntiStall, value=0
    ConstantValue233
      value:
        integer literal ConstantValue233: type=DT_TqSys_tqCkEngLimCord, value=0
    ConstantValue235
      value:
        integer literal ConstantValue235: type=DT_TqSys_tqCkIdl, value=0
    ConstantValue237
      value:
        integer literal ConstantValue237: type=DT_TqSys_tqCkIdlCord, value=0
    ConstantValue239
      value:
        integer literal ConstantValue239: type=DT_TqSys_tqCkIdlMax, value=0
    ConstantValue241
      value:
        integer literal ConstantValue241: type=DT_TqSys_tqCkIdlMin, value=0
    ConstantValue243
      value:
        integer literal ConstantValue243: type=DT_TqSys_tqIdcAirLimCordWiRes, value=0
    ConstantValue245
      value:
        integer literal ConstantValue245: type=DT_TqSys_tqIdcAirReqGen, value=0
    ConstantValue247
      value:
        integer literal ConstantValue247: type=DT_TqSys_tqIdcEngLimCord, value=0
    ConstantValue249
      value:
        integer literal ConstantValue249: type=DT_TqSys_tqIdcLvlSBPA, value=0
    ConstantValue25
      value:
        boolean literal ConstantValue25: type=DT_TqSys_bEngUHNOnIdl, value=true
    ConstantValue251
      value:
        integer literal ConstantValue251: type=DT_TqSys_tqIdcReq, value=0
    ConstantValue253
      value:
        integer literal ConstantValue253: type=DT_TqSys_tqIdcSBPA, value=0
    ConstantValue255
      value:
        integer literal ConstantValue255: type=DT_TqSys_tqIncCll, value=0
    ConstantValue257
      value:
        integer literal ConstantValue257: type=DT_TreatTDC_nCkGrd, value=0
    ConstantValue259
      value:
        integer literal ConstantValue259: type=DT_TreatTDC_nCkTDCDelta, value=0
    ConstantValue261
      value:
        integer literal ConstantValue261: type=DT_Veh_spdVeh, value=0
    ConstantValue27
      value:
        boolean literal ConstantValue27: type=DT_TqSys_bIdlAcvCmn, value=true
    ConstantValue29
      value:
        integer literal ConstantValue29: type=DT_TqSys_facAntiStall1, value=0
    ConstantValue3
      value:
        integer literal ConstantValue3: type=DT_EngLim_tqCkCurDrivFil, value=32000
    ConstantValue31
      value:
        integer literal ConstantValue31: type=DT_TqSys_facAntiStall2, value=0
    ConstantValue33
      value:
        integer literal ConstantValue33: type=DT_TqSys_facAntiStall3, value=0
    ConstantValue35
      value:
        integer literal ConstantValue35: type=DT_TqSys_facTqCkAntiStall, value=0
    ConstantValue37
      value:
        integer literal ConstantValue37: type=DT_TqSys_tqCkAOSCord, value=0
    ConstantValue39
      value:
        integer literal ConstantValue39: type=DT_TqSys_tqCkAntiStall, value=0
    ConstantValue41
      value:
        integer literal ConstantValue41: type=DT_TqSys_tqCkEngLimCord, value=0
    ConstantValue43
      value:
        integer literal ConstantValue43: type=DT_TqSys_tqCkIdlCmn, value=0
    ConstantValue45
      value:
        integer literal ConstantValue45: type=DT_TqSys_tqCkIdlCord, value=0
    ConstantValue47
      value:
        integer literal ConstantValue47: type=DT_TqSys_tqIdcAirEngIdlCord, value=0
    ConstantValue49
      value:
        integer literal ConstantValue49: type=DT_TqSys_tqIdcAirEngLimCord, value=0
    ConstantValue5
      value:
        integer literal ConstantValue5: type=DT_EngLim_tqIdcEngLimMax, value=32000
    ConstantValue51
      value:
        integer literal ConstantValue51: type=DT_TqSys_tqIdcAirLimCordWiRes, value=0
    ConstantValue53
      value:
        integer literal ConstantValue53: type=DT_TqSys_tqIdcAirLimCordWoutRes, value=0
    ConstantValue55
      value:
        integer literal ConstantValue55: type=DT_TqSys_tqIdcAirReqUnlim, value=0
    ConstantValue57
      value:
        integer literal ConstantValue57: type=DT_TqSys_tqIdcColdSmkCord, value=0
    ConstantValue59
      value:
        integer literal ConstantValue59: type=DT_TqSys_tqIdcEngIdlCord, value=0
    ConstantValue61
      value:
        integer literal ConstantValue61: type=DT_TqSys_tqIdcEngLimCord, value=0
    ConstantValue63
      value:
        boolean literal ConstantValue63: type=DT_CoCha_bAcvCll, value=false
    ConstantValue65
      value:
        integer literal ConstantValue65: type=DT_CoCha_tiTranCll, value=0
    ConstantValue67
      value:
        integer literal ConstantValue67: type=DT_CoCha_tqIncCll, value=0
    ConstantValue69
      value:
        boolean literal ConstantValue69: type=DT_CoPt_bAcvCll, value=false
    ConstantValue7
      value:
        integer literal ConstantValue7: type=DT_EngLim_tqIdcLim, value=32000
    ConstantValue71
      value:
        boolean literal ConstantValue71: type=DT_CoPt_bCluDiEgdCord, value=false
    ConstantValue73
      value:
        boolean literal ConstantValue73: type=DT_CoPt_bSIPCord, value=false
    ConstantValue75
      value:
        boolean literal ConstantValue75: type=DT_CoPt_bTqTx, value=false
    ConstantValue77
      value:
        integer literal ConstantValue77: type=DT_CoPt_noGearCord, value=0
    ConstantValue79
      value:
        integer literal ConstantValue79: type=DT_CoPt_noGearCordDrivFil, value=0
    ConstantValue81
      value:
        integer literal ConstantValue81: type=DT_CoPt_stCpl, value=0
    ConstantValue83
      value:
        integer literal ConstantValue83: type=DT_CoPt_tiTranCll, value=0
    ConstantValue85
      value:
        integer literal ConstantValue85: type=DT_CoPt_tqIdcAirCord_nCross, value=0
    ConstantValue87
      value:
        integer literal ConstantValue87: type=DT_CoPt_tqIdcAirDslCord_nReg, value=0
    ConstantValue89
      value:
        integer literal ConstantValue89: type=DT_CoPt_tqIdcReqCord_nRegReq, value=0
    ConstantValue9
      value:
        integer literal ConstantValue9: type=DT_EngLim_tqIdcMaxNReg, value=32000
    ConstantValue91
      value:
        integer literal ConstantValue91: type=DT_CoPt_tqIncCll, value=0
    ConstantValue93
      value:
        integer literal ConstantValue93: type=DT_CoVSCtl_rAccPEngTrv, value=0
    ConstantValue95
      value:
        boolean literal ConstantValue95: type=DT_DfwCtl_bAcvLimTqIdl, value=false
    ConstantValue97
      value:
        integer literal ConstantValue97: type=DT_EOM_tiEngRun, value=0
    ConstantValue99
      value:
        integer literal ConstantValue99: type=UInt8, value=0
  internal behavior IB_CoClLASl: component=COCLLASL
    data received event EV_TqSys_EveSync_CurCord:
      mode-dependency=dependent-on-mode=[R_UCE_stSt.RCD_Mode.COM_LATCH, R_UCE_stSt.RCD_Mode.INTERNAL_PARTIAL_WAKEUP, R_UCE_stSt.RCD_Mode.INTERNAL_PARTIAL_WAKEUP_APC, R_UCE_stSt.RCD_Mode.PARTIAL_WAKEUP, R_UCE_stSt.RCD_Mode.SHUTDOWN_PREPARATION, R_UCE_stSt.RCD_Mode.SHUTDOWN_PREPARATION_APC, R_UCE_stSt.RCD_Mode.TRANSITORY]
      start-on-event=RE_TqSys_EveSync_CurCord
      data=R_EV_TqSys_EveSync_CurCord.EV_TqSys_EveSync_CurCord
    timing event EV_TqSys_Sdl10ms_TqCordLim: mode-dependency=dependent-on-mode=[R_UCE_stSt.RCD_Mode.COM_LATCH, R_UCE_stSt.RCD_Mode.INTERNAL_PARTIAL_WAKEUP, R_UCE_stSt.RCD_Mode.INTERNAL_PARTIAL_WAKEUP_APC, R_UCE_stSt.RCD_Mode.PARTIAL_WAKEUP, R_UCE_stSt.RCD_Mode.SHUTDOWN_PREPARATION, R_UCE_stSt.RCD_Mode.SHUTDOWN_PREPARATION_APC, R_UCE_stSt.RCD_Mode.TRANSITORY], start-on-event=RE_TqSys_Sdl10ms_TqCordLim, period=0.01
    data received event EV_TqSys_EveSync_IdlCordLim:
      mode-dependency=dependent-on-mode=[R_UCE_stSt.RCD_Mode.COM_LATCH, R_UCE_stSt.RCD_Mode.INTERNAL_PARTIAL_WAKEUP, R_UCE_stSt.RCD_Mode.INTERNAL_PARTIAL_WAKEUP_APC, R_UCE_stSt.RCD_Mode.PARTIAL_WAKEUP, R_UCE_stSt.RCD_Mode.SHUTDOWN_PREPARATION, R_UCE_stSt.RCD_Mode.SHUTDOWN_PREPARATION_APC, R_UCE_stSt.RCD_Mode.TRANSITORY]
      start-on-event=RE_TqSys_EveSync_IdlCordLim
      data=R_EV_TqSys_EveSync_IdlCordLim.EV_TqSys_EveSync_IdlCordLim
    data received event EV_TqSys_EveSync_VarAntiStall:
      mode-dependency=dependent-on-mode=[R_UCE_stSt.RCD_Mode.COM_LATCH, R_UCE_stSt.RCD_Mode.INTERNAL_PARTIAL_WAKEUP, R_UCE_stSt.RCD_Mode.INTERNAL_PARTIAL_WAKEUP_APC, R_UCE_stSt.RCD_Mode.PARTIAL_WAKEUP, R_UCE_stSt.RCD_Mode.SHUTDOWN_PREPARATION, R_UCE_stSt.RCD_Mode.SHUTDOWN_PREPARATION_APC, R_UCE_stSt.RCD_Mode.TRANSITORY]
      start-on-event=RE_TqSys_EveSync_VarAntiStall
      data=R_EV_TqSys_EveSync_VarAntiStall.EV_TqSys_EveSync_VarAntiStall
    data received event EV_TqSys_EveSync_TqCll:
      mode-dependency=dependent-on-mode=[R_UCE_stSt.RCD_Mode.COM_LATCH, R_UCE_stSt.RCD_Mode.INTERNAL_PARTIAL_WAKEUP, R_UCE_stSt.RCD_Mode.INTERNAL_PARTIAL_WAKEUP_APC, R_UCE_stSt.RCD_Mode.PARTIAL_WAKEUP, R_UCE_stSt.RCD_Mode.SHUTDOWN_PREPARATION, R_UCE_stSt.RCD_Mode.SHUTDOWN_PREPARATION_APC, R_UCE_stSt.RCD_Mode.TRANSITORY]
      start-on-event=RE_TqSys_EveSync_TqCll
      data=R_EV_TqSys_EveSync_TqCll.EV_TqSys_EveSync_TqCll
    mode switch event EV_CoClLASl_001_MSE: start-on-event=RE_CoClLASl_001_MSE, activation=ENTRY, mode=R_EcuM_CurrentMode.currentMode.RUN
    data received event EV_TqSys_EveSync_CoPtAntiStall:
      mode-dependency=dependent-on-mode=[R_UCE_stSt.RCD_Mode.COM_LATCH, R_UCE_stSt.RCD_Mode.INTERNAL_PARTIAL_WAKEUP, R_UCE_stSt.RCD_Mode.INTERNAL_PARTIAL_WAKEUP_APC, R_UCE_stSt.RCD_Mode.PARTIAL_WAKEUP, R_UCE_stSt.RCD_Mode.SHUTDOWN_PREPARATION, R_UCE_stSt.RCD_Mode.SHUTDOWN_PREPARATION_APC, R_UCE_stSt.RCD_Mode.TRANSITORY]
      start-on-event=RE_TqSys_EveSync_CoPtAntiStall
      data=R_EV_TqSys_EveSync_CoPtAntiStall.EV_TqSys_EveSync_CoPtAntiStall
    timing event EV_TqSys_Sdl10ms_IdlCordLim: mode-dependency=dependent-on-mode=[R_UCE_stSt.RCD_Mode.COM_LATCH, R_UCE_stSt.RCD_Mode.INTERNAL_PARTIAL_WAKEUP, R_UCE_stSt.RCD_Mode.INTERNAL_PARTIAL_WAKEUP_APC, R_UCE_stSt.RCD_Mode.PARTIAL_WAKEUP, R_UCE_stSt.RCD_Mode.SHUTDOWN_PREPARATION, R_UCE_stSt.RCD_Mode.SHUTDOWN_PREPARATION_APC, R_UCE_stSt.RCD_Mode.TRANSITORY], start-on-event=RE_TqSys_Sdl10ms_IdlCordLim, period=0.01
    data received event EV_TqSys_EveSync_TqCordLim:
      mode-dependency=dependent-on-mode=[R_UCE_stSt.RCD_Mode.COM_LATCH, R_UCE_stSt.RCD_Mode.INTERNAL_PARTIAL_WAKEUP, R_UCE_stSt.RCD_Mode.INTERNAL_PARTIAL_WAKEUP_APC, R_UCE_stSt.RCD_Mode.PARTIAL_WAKEUP, R_UCE_stSt.RCD_Mode.SHUTDOWN_PREPARATION, R_UCE_stSt.RCD_Mode.SHUTDOWN_PREPARATION_APC, R_UCE_stSt.RCD_Mode.TRANSITORY]
      start-on-event=RE_TqSys_EveSync_TqCordLim
      data=R_EV_TqSys_EveSync_TqCordLim.EV_TqSys_EveSync_TqCordLim
    data received event EV_TqSys_EveSync_AntiStallReg:
      mode-dependency=dependent-on-mode=[R_UCE_stSt.RCD_Mode.COM_LATCH, R_UCE_stSt.RCD_Mode.INTERNAL_PARTIAL_WAKEUP, R_UCE_stSt.RCD_Mode.INTERNAL_PARTIAL_WAKEUP_APC, R_UCE_stSt.RCD_Mode.PARTIAL_WAKEUP, R_UCE_stSt.RCD_Mode.SHUTDOWN_PREPARATION, R_UCE_stSt.RCD_Mode.SHUTDOWN_PREPARATION_APC, R_UCE_stSt.RCD_Mode.TRANSITORY]
      start-on-event=RE_TqSys_EveSync_AntiStallReg
      data=R_EV_TqSys_EveSync_AntiStallReg.EV_TqSys_EveSync_AntiStallReg
    4 x inter runnable variable, all with sw-calibration-access=READ-WRITE, communication-approach=EXPLICIT:
      EngLim_tqIdcAirLimAfterRes_irv: type=DT_EngLim_tqIdcAirLimAfterRes_irv, init-value=C_SInt16_32000
      EngLim_tqIdcAirLim_irv: type=DT_EngLim_tqIdcAirLim_irv, init-value=C_SInt16_32000263
      IdlSys_tqIdcIdlAirSBPA_irv: type=DT_IdlSys_tqIdcIdlAirSBPA_irv, init-value=C_SInt16_32000265
      TqSys_bAcvAntiStallAut_irv: type=DT_TqSys_bAcvAntiStallAut_irv, init-value=C_Boolean_False
    10 x runnable:
      RE_CoClLASl_001_MSE: written-variable=[IdlSys_tqIdcIdlAirSBPA_irv, TqSys_bAcvAntiStallAut_irv, EngLim_tqIdcAirLim_irv, EngLim_tqIdcAirLimAfterRes_irv]  # RE_080939_10ms_init
        32 x data send point:
          ds_EngLim_tqCkCurDrivFil: data-element=P_EngLim_tqCkCurDrivFil.EngLim_tqCkCurDrivFil
          ds_TqSys_tqCkIdlCord: data-element=P_TqSys_tqCkIdlCord.TqSys_tqCkIdlCord
          ds_EngLim_tqIdcLim: data-element=P_EngLim_tqIdcLim.EngLim_tqIdcLim
          ds_TqSys_bAcvAntiStallMan: data-element=P_TqSys_bAcvAntiStallMan.TqSys_bAcvAntiStallMan
          ds_TqSys_tqIdcAirReqUnlim: data-element=P_TqSys_tqIdcAirReqUnlim.TqSys_tqIdcAirReqUnlim
          ds_EngLim_tqIdcEngLimMax: data-element=P_EngLim_tqIdcEngLimMax.EngLim_tqIdcEngLimMax
          ds_TqCll_bReqCllPtl: data-element=P_TqCll_bReqCllPtl.TqCll_bReqCllPtl
          ds_TqCll_bAcvCll: data-element=P_TqCll_bAcvCll.TqCll_bAcvCll
          ds_TqSys_tqCkAntiStall: data-element=P_TqSys_tqCkAntiStall.TqSys_tqCkAntiStall
          ds_TqSys_tqIdcAirEngIdlCord: data-element=P_TqSys_tqIdcAirEngIdlCord.TqSys_tqIdcAirEngIdlCord
          ds_ESLim_bAcvEngSpdLim: data-element=P_ESLim_bAcvEngSpdLim.ESLim_bAcvEngSpdLim
          ds_TqSys_bEngUHNOnIdl: data-element=P_TqSys_bEngUHNOnIdl.TqSys_bEngUHNOnIdl
          ds_TqSys_facAntiStall3: data-element=P_TqSys_facAntiStall3.TqSys_facAntiStall3
          ds_TqSys_tqCkIdlCmn: data-element=P_TqSys_tqCkIdlCmn.TqSys_tqCkIdlCmn
          ds_TqSys_facAntiStall2: data-element=P_TqSys_facAntiStall2.TqSys_facAntiStall2
          ds_TqSys_tqIdcAirEngLimCord: data-element=P_TqSys_tqIdcAirEngLimCord.TqSys_tqIdcAirEngLimCord
          ds_TqSys_tqCkAOSCord: data-element=P_TqSys_tqCkAOSCord.TqSys_tqCkAOSCord
          ds_TqSys_bIdlAcvCmn: data-element=P_TqSys_bIdlAcvCmn.TqSys_bIdlAcvCmn
          ds_TqSys_tqCkEngLimCord: data-element=P_TqSys_tqCkEngLimCord.TqSys_tqCkEngLimCord
          ds_TqSys_bAcvAntiStall: data-element=P_TqSys_bAcvAntiStall.TqSys_bAcvAntiStall
          ds_TqCll_bForcCll: data-element=P_TqCll_bForcCll.TqCll_bForcCll
          ds_EngLim_tqIdcMaxNReg: data-element=P_EngLim_tqIdcMaxNReg.EngLim_tqIdcMaxNReg
          ds_TqSys_tqIdcEngLimCord: data-element=P_TqSys_tqIdcEngLimCord.TqSys_tqIdcEngLimCord
          ds_TqSys_bEngNOnIdl: data-element=P_TqSys_bEngNOnIdl.TqSys_bEngNOnIdl
          ds_TqSys_facAntiStall1: data-element=P_TqSys_facAntiStall1.TqSys_facAntiStall1
          ds_TqSys_tqIdcEngIdlCord: data-element=P_TqSys_tqIdcEngIdlCord.TqSys_tqIdcEngIdlCord
          ds_TqSys_facTqCkAntiStall: data-element=P_TqSys_facTqCkAntiStall.TqSys_facTqCkAntiStall
          ds_TqSys_bAcvAntiStallSmk: data-element=P_TqSys_bAcvAntiStallSmk.TqSys_bAcvAntiStallSmk
          ds_TqSys_tqIdcAirLimCordWiRes: data-element=P_TqSys_tqIdcAirLimCordWiRes.TqSys_tqIdcAirLimCordWiRes
          ds_TqSys_tqIdcColdSmkCord: data-element=P_TqSys_tqIdcColdSmkCord.TqSys_tqIdcColdSmkCord
          ds_TqSys_tqIdcAirLimCordWoutRes: data-element=P_TqSys_tqIdcAirLimCordWoutRes.TqSys_tqIdcAirLimCordWoutRes
          ds_CoPt_bAcvAntiStallFil: data-element=P_CoPt_bAcvAntiStallFil.CoPt_bAcvAntiStallFil
        sync call ssp_GetTimer_1ms_U32: operation=R_CoClLASl_GetTimer_1ms_U32.GetTimer_1ms_U32
      RE_TqSys_EveSync_TqCll
        32 x data receive point:
          dr_TqAdvMin_tqIncCll: data-element=R_TqAdvMin_tqIncCll.TqAdvMin_tqIncCll
          dr_IdlSys_tiTranCll: data-element=R_IdlSys_tiTranCll.IdlSys_tiTranCll
          dr_TqRes_tiTranCll: data-element=R_TqRes_tiTranCll.TqRes_tiTranCll
          dr_TqSys_tqIdcAirReqGen: data-element=R_TqSys_tqIdcAirReqGen.TqSys_tqIdcAirReqGen
          dr_TqSys_tqIdcEngLimCord: data-element=R_TqSys_tqIdcEngLimCord.TqSys_tqIdcEngLimCord
          dr_IdlSys_tqIncCll: data-element=R_IdlSys_tqIncCll.IdlSys_tqIncCll
          dr_EngLim_tqIdcEngCurMax: data-element=R_EngLim_tqIdcEngCurMax.EngLim_tqIdcEngCurMax
          dr_TqRes_bAcvCll: data-element=R_TqRes_bAcvCll.TqRes_bAcvCll
          dr_TqSys_bEngNOnIdl: data-element=R_TqSys_bEngNOnIdl.TqSys_bEngNOnIdl
          dr_Ext_tiTDC: data-element=R_Ext_tiTDC.Ext_tiTDC
          dr_EngLim_tiTranCll: data-element=R_EngLim_tiTranCll.EngLim_tiTranCll
          dr_CoPt_tqIncCll: data-element=R_CoPt_tqIncCll.CoPt_tqIncCll
          dr_CoCha_tiTranCll: data-element=R_CoCha_tiTranCll.CoCha_tiTranCll
          dr_TqAdvMin_tiTranCll: data-element=R_TqAdvMin_tiTranCll.TqAdvMin_tiTranCll
          dr_TqSys_bAOSAcv: data-element=R_TqSys_bAOSAcv.TqSys_bAOSAcv
          dr_Eng_bAcvCllEngReq: data-element=R_Eng_bAcvCllEngReq.Eng_bAcvCllEngReq
          dr_EngLim_tqIncCll: data-element=R_EngLim_tqIncCll.EngLim_tqIncCll
          dr_EngLim_bAcvCll: data-element=R_EngLim_bAcvCll.EngLim_bAcvCll
          dr_CoPt_noGearCordDrivFil: data-element=R_CoPt_noGearCordDrivFil.CoPt_noGearCordDrivFil
          dr_TqSys_bTypFu: data-element=R_TqSys_bTypFu.TqSys_bTypFu
          dr_IdlSys_bAcvCll: data-element=R_IdlSys_bAcvCll.IdlSys_bAcvCll
          dr_TqAdvMin_bAcvCll: data-element=R_TqAdvMin_bAcvCll.TqAdvMin_bAcvCll
          dr_TqSys_tqIncCll: data-element=R_TqSys_tqIncCll.TqSys_tqIncCll
          dr_CoPt_bAcvCll: data-element=R_CoPt_bAcvCll.CoPt_bAcvCll
          dr_TqRes_tqIncCll: data-element=R_TqRes_tqIncCll.TqRes_tqIncCll
          dr_CoCha_tqIncCll: data-element=R_CoCha_tqIncCll.CoCha_tqIncCll
          dr_Eng_nCkFil: data-element=R_Eng_nCkFil.Eng_nCkFil
          dr_TqSys_tiTranCll: data-element=R_TqSys_tiTranCll.TqSys_tiTranCll
          dr_CoCha_bAcvCll: data-element=R_CoCha_bAcvCll.CoCha_bAcvCll
          dr_TqSys_bAcvCll: data-element=R_TqSys_bAcvCll.TqSys_bAcvCll
          dr_IdlSys_bAcvIdlCtl: data-element=R_IdlSys_bAcvIdlCtl.IdlSys_bAcvIdlCtl
          dr_CoPt_tiTranCll: data-element=R_CoPt_tiTranCll.CoPt_tiTranCll
        4 x data send point:
          ds_TqCll_bReqCllPtl: data-element=P_TqCll_bReqCllPtl.TqCll_bReqCllPtl
          ds_TqSys_tqCkEngLimCord: data-element=P_TqSys_tqCkEngLimCord.TqSys_tqCkEngLimCord
          ds_TqCll_bAcvCll: data-element=P_TqCll_bAcvCll.TqCll_bAcvCll
          ds_TqCll_bForcCll: data-element=P_TqCll_bForcCll.TqCll_bForcCll
        sync call ssp_FRM_bInhTqCll: operation=R_FRM_bInhTqCll.GetFunctionPermission
        sync call ssp_GetTimer_1ms_U32: operation=R_CoClLASl_GetTimer_1ms_U32.GetTimer_1ms_U32
      RE_TqSys_EveSync_TqCordLim
        12 x data receive point:
          dr_EngLim_tqIdcEngLim: data-element=R_EngLim_tqIdcEngLim.EngLim_tqIdcEngLim
          dr_EngLim_tqIdcRed: data-element=R_EngLim_tqIdcRed.EngLim_tqIdcRed
          dr_Ext_nEng: data-element=R_Ext_nEng.Ext_nEng
          dr_TqSys_tqIdcSBPA: data-element=R_TqSys_tqIdcSBPA.TqSys_tqIdcSBPA
          dr_EngLim_tqIdcSyst: data-element=R_EngLim_tqIdcSyst.EngLim_tqIdcSyst
          dr_TqDem_tqIdcLimNReg: data-element=R_TqDem_tqIdcLimNReg.TqDem_tqIdcLimNReg
          dr_CoPt_noGearCord: data-element=R_CoPt_noGearCord.CoPt_noGearCord
          dr_TqSys_bTypFu: data-element=R_TqSys_bTypFu.TqSys_bTypFu
          dr_EngLim_tqIdcEngProt: data-element=R_EngLim_tqIdcEngProt.EngLim_tqIdcEngProt
          dr_EngLim_tqIdcSfty: data-element=R_EngLim_tqIdcSfty.EngLim_tqIdcSfty
          dr_EngLim_tqIdcEngCurMax: data-element=R_EngLim_tqIdcEngCurMax.EngLim_tqIdcEngCurMax
          dr_EngLim_tqIdcPresUsThrMax: data-element=R_EngLim_tqIdcPresUsThrMax.EngLim_tqIdcPresUsThrMax
        4 x data send point:
          ds_EngLim_tqIdcLim: data-element=P_EngLim_tqIdcLim.EngLim_tqIdcLim
          ds_EngLim_tqIdcMaxNReg: data-element=P_EngLim_tqIdcMaxNReg.EngLim_tqIdcMaxNReg
          ds_EngLim_tqIdcEngLimMax: data-element=P_EngLim_tqIdcEngLimMax.EngLim_tqIdcEngLimMax
          ds_EngLim_tqCkCurDrivFil: data-element=P_EngLim_tqCkCurDrivFil.EngLim_tqCkCurDrivFil
        sync call ssp_GetTimer_1ms_U32: operation=R_CoClLASl_GetTimer_1ms_U32.GetTimer_1ms_U32
      RE_TqSys_EveSync_VarAntiStall
        12 x data receive point:
          dr_TqSys_nTarDynIdl: data-element=R_TqSys_nTarDynIdl.TqSys_nTarDynIdl
          dr_TreatTDC_nCkGrd: data-element=R_TreatTDC_nCkGrd.TreatTDC_nCkGrd
          dr_TqSys_bIdlAcvCmn: data-element=R_TqSys_bIdlAcvCmn.TqSys_bIdlAcvCmn
          dr_CoPt_bCluDiEgdCord: data-element=R_CoPt_bCluDiEgdCord.CoPt_bCluDiEgdCord
          dr_TreatTDC_nCkTDCDelta: data-element=R_TreatTDC_nCkTDCDelta.TreatTDC_nCkTDCDelta
          dr_Ext_tiTDC: data-element=R_Ext_tiTDC.Ext_tiTDC
          dr_EOM_tiEngRun: data-element=R_EOM_tiEngRun.EOM_tiEngRun
          dr_Ext_tCoMes: data-element=R_Ext_tCoMes.Ext_tCoMes
          dr_Ext_nEng: data-element=R_Ext_nEng.Ext_nEng
          dr_TqSys_tqIdcReq: data-element=R_TqSys_tqIdcReq.TqSys_tqIdcReq
          dr_Ext_stGBxCf: data-element=R_Ext_stGBxCf.Ext_stGBxCf
          dr_TqSys_bTypFu: data-element=R_TqSys_bTypFu.TqSys_bTypFu
        5 x data send point:
          ds_TqSys_facAntiStall2: data-element=P_TqSys_facAntiStall2.TqSys_facAntiStall2
          ds_TqSys_bAcvAntiStallMan: data-element=P_TqSys_bAcvAntiStallMan.TqSys_bAcvAntiStallMan
          ds_TqSys_facAntiStall3: data-element=P_TqSys_facAntiStall3.TqSys_facAntiStall3
          ds_TqSys_facTqCkAntiStall: data-element=P_TqSys_facTqCkAntiStall.TqSys_facTqCkAntiStall
          ds_TqSys_facAntiStall1: data-element=P_TqSys_facAntiStall1.TqSys_facAntiStall1
        sync call ssp_GetTimer_1ms_U32: operation=R_CoClLASl_GetTimer_1ms_U32.GetTimer_1ms_U32
      RE_TqSys_EveSync_CoPtAntiStall: written-variable=TqSys_bAcvAntiStallAut_irv
        9 x data receive point:
          dr_Ext_tCoMes: data-element=R_Ext_tCoMes.Ext_tCoMes
          dr_TreatTDC_nCkGrd: data-element=R_TreatTDC_nCkGrd.TreatTDC_nCkGrd
          dr_Ext_stGBxCf: data-element=R_Ext_stGBxCf.Ext_stGBxCf
          dr_CoPt_bTqTx: data-element=R_CoPt_bTqTx.CoPt_bTqTx
          dr_Ext_tiTDC: data-element=R_Ext_tiTDC.Ext_tiTDC
          dr_CoBrk_bAcvBrk: data-element=R_CoBrk_bAcvBrk.CoBrk_bAcvBrk
          dr_Ext_nEng: data-element=R_Ext_nEng.Ext_nEng
          dr_Veh_spdVeh: data-element=R_Veh_spdVeh.Veh_spdVeh
          dr_CoPt_stCpl: data-element=R_CoPt_stCpl.CoPt_stCpl
        data send point ds_TqSys_bAcvAntiStallSmk: data-element=P_TqSys_bAcvAntiStallSmk.TqSys_bAcvAntiStallSmk
        data send point ds_CoPt_bAcvAntiStallFil: data-element=P_CoPt_bAcvAntiStallFil.CoPt_bAcvAntiStallFil
        5 x sync call:
          ssp_GetTimer_1ms_U32: operation=R_CoClLASl_GetTimer_1ms_U32.GetTimer_1ms_U32
          ssp_FRM_bInhCoPtBrk: operation=R_FRM_bInhCoPtBrk.GetFunctionPermission
          ssp_FRM_bInhCoPtStPt: operation=R_FRM_bInhCoPtStPt.GetFunctionPermission
          ssp_FRM_bInhCoPtSpdVeh: operation=R_FRM_bInhCoPtSpdVeh.GetFunctionPermission
          ssp_FRM_bInhCoPtTCo: operation=R_FRM_bInhCoPtTCo.GetFunctionPermission
      RE_TqSys_Sdl10ms_IdlCordLim: read-variable=[EngLim_tqIdcAirLimAfterRes_irv, EngLim_tqIdcAirLim_irv, IdlSys_tqIdcIdlAirSBPA_irv]
        7 x data receive point:
          dr_CoPt_tqIdcAirDslCord_nReg: data-element=R_CoPt_tqIdcAirDslCord_nReg.CoPt_tqIdcAirDslCord_nReg
          dr_EngLim_tqIdcRed: data-element=R_EngLim_tqIdcRed.EngLim_tqIdcRed
          dr_IdlSys_tqIdcAirIdl: data-element=R_IdlSys_tqIdcAirIdl.IdlSys_tqIdcAirIdl
          dr_TqSys_tqCkIdlCord: data-element=R_TqSys_tqCkIdlCord.TqSys_tqCkIdlCord
          dr_CoPt_tqIdcAirCord_nCross: data-element=R_CoPt_tqIdcAirCord_nCross.CoPt_tqIdcAirCord_nCross
          dr_TqSys_bTypFu: data-element=R_TqSys_bTypFu.TqSys_bTypFu
          dr_TqRes_tqMaxRes: data-element=R_TqRes_tqMaxRes.TqRes_tqMaxRes
        5 x data send point:
          ds_TqSys_tqIdcAirLimCordWoutRes: data-element=P_TqSys_tqIdcAirLimCordWoutRes.TqSys_tqIdcAirLimCordWoutRes
          ds_TqSys_tqIdcAirEngIdlCord: data-element=P_TqSys_tqIdcAirEngIdlCord.TqSys_tqIdcAirEngIdlCord
          ds_TqSys_tqIdcAirLimCordWiRes: data-element=P_TqSys_tqIdcAirLimCordWiRes.TqSys_tqIdcAirLimCordWiRes
          ds_TqSys_tqIdcAirReqUnlim: data-element=P_TqSys_tqIdcAirReqUnlim.TqSys_tqIdcAirReqUnlim
          ds_TqSys_tqIdcAirEngLimCord: data-element=P_TqSys_tqIdcAirEngLimCord.TqSys_tqIdcAirEngLimCord
        sync call ssp_GetTimer_1ms_U32: operation=R_CoClLASl_GetTimer_1ms_U32.GetTimer_1ms_U32
      RE_TqSys_EveSync_AntiStallReg
        9 x data receive point:
          dr_TqSys_facAntiStall2: data-element=R_TqSys_facAntiStall2.TqSys_facAntiStall2
          dr_Ext_nEng2: data-element=R_Ext_nEng2.Ext_nEng2
          dr_TqSys_tqCkIdlMax: data-element=R_TqSys_tqCkIdlMax.TqSys_tqCkIdlMax
          dr_TqSys_facAntiStall1: data-element=R_TqSys_facAntiStall1.TqSys_facAntiStall1
          dr_TqSys_facTqCkAntiStall: data-element=R_TqSys_facTqCkAntiStall.TqSys_facTqCkAntiStall
          dr_TqSys_facAntiStall3: data-element=R_TqSys_facAntiStall3.TqSys_facAntiStall3
          dr_Ext_nEng1: data-element=R_Ext_nEng1.Ext_nEng1
          dr_TqSys_tqCkIdl: data-element=R_TqSys_tqCkIdl.TqSys_tqCkIdl
          dr_TqSys_tqCkIdlMin: data-element=R_TqSys_tqCkIdlMin.TqSys_tqCkIdlMin
        data send point ds_TqSys_tqCkAntiStall: data-element=P_TqSys_tqCkAntiStall.TqSys_tqCkAntiStall
        sync call ssp_GetTimer_1ms_U32: operation=R_CoClLASl_GetTimer_1ms_U32.GetTimer_1ms_U32
      RE_TqSys_EveSync_IdlCordLim: read-variable=TqSys_bAcvAntiStallAut_irv, written-variable=IdlSys_tqIdcIdlAirSBPA_irv
        23 x data receive point:
          dr_TqSys_facReqExhTempProt: data-element=R_TqSys_facReqExhTempProt.TqSys_facReqExhTempProt
          dr_CoPt_tqIdcReqCord_nRegReq: data-element=R_CoPt_tqIdcReqCord_nRegReq.CoPt_tqIdcReqCord_nRegReq
          dr_TqSys_bAcvAntiStallMan: data-element=R_TqSys_bAcvAntiStallMan.TqSys_bAcvAntiStallMan
          dr_TqSys_nTarIdl: data-element=R_TqSys_nTarIdl.TqSys_nTarIdl
          dr_Ext_nEng: data-element=R_Ext_nEng.Ext_nEng
          dr_IdlSys_bAcvAntiStall: data-element=R_IdlSys_bAcvAntiStall.IdlSys_bAcvAntiStall
          dr_TqSys_tqCkAntiStall: data-element=R_TqSys_tqCkAntiStall.TqSys_tqCkAntiStall
          dr_IdlSys_tqIdcIdl: data-element=R_IdlSys_tqIdcIdl.IdlSys_tqIdcIdl
          dr_CoVSCtl_rAccPEngTrv: data-element=R_CoVSCtl_rAccPEngTrv.CoVSCtl_rAccPEngTrv
          dr_Ext_tiTDC: data-element=R_Ext_tiTDC.Ext_tiTDC
          dr_TqSys_bIdlAcv: data-element=R_TqSys_bIdlAcv.TqSys_bIdlAcv
          dr_Ext_stGBxCf: data-element=R_Ext_stGBxCf.Ext_stGBxCf
          dr_TqSys_bTypFu: data-element=R_TqSys_bTypFu.TqSys_bTypFu
          dr_TqSys_tqCkIdl: data-element=R_TqSys_tqCkIdl.TqSys_tqCkIdl
          dr_EngLim_tqIdcColdSmkRaw: data-element=R_EngLim_tqIdcColdSmkRaw.EngLim_tqIdcColdSmkRaw
          dr_TqSys_facReqFuelRunDry: data-element=R_TqSys_facReqFuelRunDry.TqSys_facReqFuelRunDry
          dr_DfwCtl_bAcvLimTqIdl: data-element=R_DfwCtl_bAcvLimTqIdl.DfwCtl_bAcvLimTqIdl
          dr_IdlSys_bAcvIdlCtl: data-element=R_IdlSys_bAcvIdlCtl.IdlSys_bAcvIdlCtl
          dr_EngLim_tqIdcLim: data-element=R_EngLim_tqIdcLim.EngLim_tqIdcLim
          dr_CoPt_bSIPCord: data-element=R_CoPt_bSIPCord.CoPt_bSIPCord
          dr_TqSys_tqIdcLvlSBPA: data-element=R_TqSys_tqIdcLvlSBPA.TqSys_tqIdcLvlSBPA
          dr_EngLim_tqIdcRed: data-element=R_EngLim_tqIdcRed.EngLim_tqIdcRed
          dr_TqCmp_tqSumLossCmp: data-element=R_TqCmp_tqSumLossCmp.TqCmp_tqSumLossCmp
        9 x data send point:
          ds_TqSys_tqIdcEngLimCord: data-element=P_TqSys_tqIdcEngLimCord.TqSys_tqIdcEngLimCord
          ds_TqSys_tqCkIdlCmn: data-element=P_TqSys_tqCkIdlCmn.TqSys_tqCkIdlCmn
          ds_TqSys_tqIdcEngIdlCord: data-element=P_TqSys_tqIdcEngIdlCord.TqSys_tqIdcEngIdlCord
          ds_TqSys_bIdlAcvCmn: data-element=P_TqSys_bIdlAcvCmn.TqSys_bIdlAcvCmn
          ds_TqSys_tqCkIdlCord: data-element=P_TqSys_tqCkIdlCord.TqSys_tqCkIdlCord
          ds_TqSys_bEngNOnIdl: data-element=P_TqSys_bEngNOnIdl.TqSys_bEngNOnIdl
          ds_TqSys_bEngUHNOnIdl: data-element=P_TqSys_bEngUHNOnIdl.TqSys_bEngUHNOnIdl
          ds_TqSys_tqIdcColdSmkCord: data-element=P_TqSys_tqIdcColdSmkCord.TqSys_tqIdcColdSmkCord
          ds_TqSys_bAcvAntiStall: data-element=P_TqSys_bAcvAntiStall.TqSys_bAcvAntiStall
        sync call ssp_GetTimer_1ms_U32: operation=R_CoClLASl_GetTimer_1ms_U32.GetTimer_1ms_U32
      RE_TqSys_Sdl10ms_TqCordLim: written-variable=[EngLim_tqIdcAirLimAfterRes_irv, EngLim_tqIdcAirLim_irv]
        8 x data receive point:
          dr_EngLim_tqIdcAirResMax: data-element=R_EngLim_tqIdcAirResMax.EngLim_tqIdcAirResMax
          dr_EngLim_tqIdcPresUsThrMax: data-element=R_EngLim_tqIdcPresUsThrMax.EngLim_tqIdcPresUsThrMax
          dr_EngLim_tqIdcEngProt: data-element=R_EngLim_tqIdcEngProt.EngLim_tqIdcEngProt
          dr_EngLim_tqIdcSyst: data-element=R_EngLim_tqIdcSyst.EngLim_tqIdcSyst
          dr_ThMgt_tqIdcLimReq: data-element=R_ThMgt_tqIdcLimReq.ThMgt_tqIdcLimReq
          dr_TqSys_tqIdcAirLimCordWiRes: data-element=R_TqSys_tqIdcAirLimCordWiRes.TqSys_tqIdcAirLimCordWiRes
          dr_TqDem_tqIdcLimNReg: data-element=R_TqDem_tqIdcLimNReg.TqDem_tqIdcLimNReg
          dr_EngLim_tqIdcAdvOptmTrbMax: data-element=R_EngLim_tqIdcAdvOptmTrbMax.EngLim_tqIdcAdvOptmTrbMax
        data send point ds_ESLim_bAcvEngSpdLim: data-element=P_ESLim_bAcvEngSpdLim.ESLim_bAcvEngSpdLim
        sync call ssp_GetTimer_1ms_U32: operation=R_CoClLASl_GetTimer_1ms_U32.GetTimer_1ms_U32
      RE_TqSys_EveSync_CurCord
        4 x data receive point:
          dr_TqSys_tqCkEngLimCord: data-element=R_TqSys_tqCkEngLimCord.TqSys_tqCkEngLimCord
          dr_TqSys_tqAOSCVC: data-element=R_TqSys_tqAOSCVC.TqSys_tqAOSCVC
          dr_TqSys_tqCkAOSCor: data-element=R_TqSys_tqCkAOSCor.TqSys_tqCkAOSCor
          dr_EngLim_tqCkCurDrivFil: data-element=R_EngLim_tqCkCurDrivFil.EngLim_tqCkCurDrivFil
        data send point ds_TqSys_tqCkAOSCord: data-element=P_TqSys_tqCkAOSCord.TqSys_tqCkAOSCord
        sync call ssp_GetTimer_1ms_U32: operation=R_CoClLASl_GetTimer_1ms_U32.GetTimer_1ms_U32
  swc implementation Imp_CoClLASl: programming-language=C, behavior=IB_CoClLASl
    code-descriptors:
      code CodeDescriptor: type=SRC
        12 x xfile:
          COCLLASL_Anti_Stall_Param_c: url=COCLLASL_Anti_Stall_Param.c
          COCLLASL_Req_Cll_Opl_Gbl_c: url=COCLLASL_Req_Cll_Opl_Gbl.c
          COCLLASL_Cmi_Lim_Cord_Sync_c: url=COCLLASL_Cmi_Lim_Cord_Sync.c
          COCLLASL_Idl_Coord_Lim_c: url=COCLLASL_Idl_Coord_Lim.c
          COCLLASL_Bva_Bmp_Anti_Stall_c: url=COCLLASL_Bva_Bmp_Anti_Stall.c
          COCLLASL_Cmi_Lim_Cord_c: url=COCLLASL_Cmi_Lim_Cord.c
          CoClLASl_MemMap_h: url=CoClLASl_MemMap.h
          COCLLASL_Trq_Aos_Coord_c: url=COCLLASL_Trq_Aos_Coord.c
          CoClLASl_c: url=CoClLASl.c
          CoClLASl_h: url=CoClLASl.h
          COCLLASL_Bvm_Anti_Stall_Reg_c: url=COCLLASL_Bvm_Anti_Stall_Reg.c
          COCLLASL_Idl_Coord_Lim_Sync_c: url=COCLLASL_Idl_Coord_Lim_Sync.c
package /Components/SWC_CoClLASl/CoClLASl_IRVDatatypes
  boolean type DT_TqSys_bAcvAntiStallAut_irv: base-type=boolean
  integer type DT_EngLim_tqIdcAirLim_irv: base-type=int16, lower-limit=-32768, upper-limit=32767
  integer type DT_EngLim_tqIdcAirLimAfterRes_irv: base-type=int16, lower-limit=-32768, upper-limit=32767
  integer type DT_IdlSys_tqIdcIdlAirSBPA_irv: base-type=int16, lower-limit=-32768, upper-limit=32767
